# ADSP-2183xW_HPC register map
Vendor: Analog Devices; Series: ADSP-2183xW_HPC; File version: 3.0.3.517
CPU: 
Registers are 32-bit, read-write, reset 0x0 unless marked. A register's access mark holds for its fields unless they carry their own. Offsets are from the block's base; [hi:lo] are bit positions; 'fields as' and 'values as' point back to an identical list.

## MEC1 — Memory Error Controller
Base 0x310A3000
Same registers: MEC2 0x310A4000
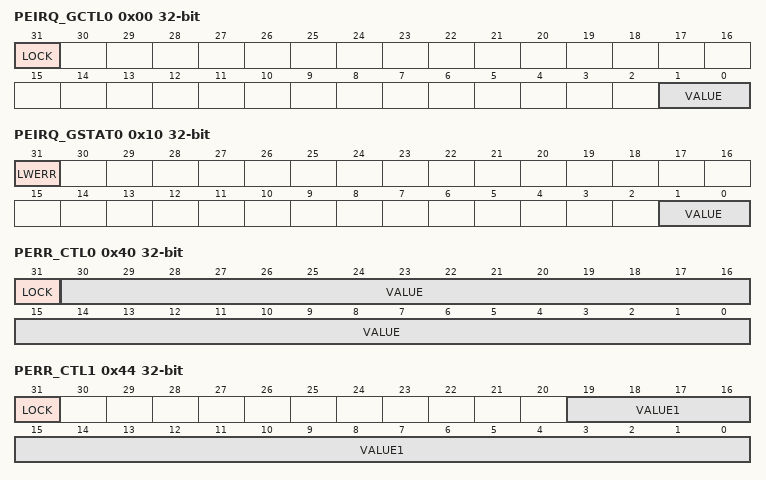
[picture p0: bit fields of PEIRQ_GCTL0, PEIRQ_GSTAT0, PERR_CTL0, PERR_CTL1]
0x00 PEIRQ_GCTL0 — Parity Error Interrupt Request Global Control Register
  [31] LOCK — Parity Error Global Control Register Lock
    0=UNLOCK; 1=LOCK
  [1:0] VALUE range 0x00000000..0x00000003 — VALUE[1:0] Parity Error Global Control
0x10 PEIRQ_GSTAT0 — Parity Error Interrupt Request Global Status Register
  [31] LWERR — Parity Error Global Control Register Lock Write Error
    0=NO_LWERR (No Error); 1=LWERR (Error Occurred)
  [1:0] VALUE ro — VALUE[1:0] Parity Error Global Status
0x40 PERR_CTL0 — Parity Error Control Register
  [31] LOCK
    0=UNLOCK; 1=LOCK
  [30:0] VALUE — Parity Error Control
    32=M33_CODERAM_PE (M33 CodeRAM Parity Error); 64=M33_DATARAM_PE (M33 DataRAM Parity Error)
0x44 PERR_CTL1 — Parity Error Control Register
  [31] LOCK
    0=UNLOCK; 1=LOCK
  [19:0] VALUE1 range 0x00000000..0x000FFFFF — VALUE1[19:0] Parity Error Control
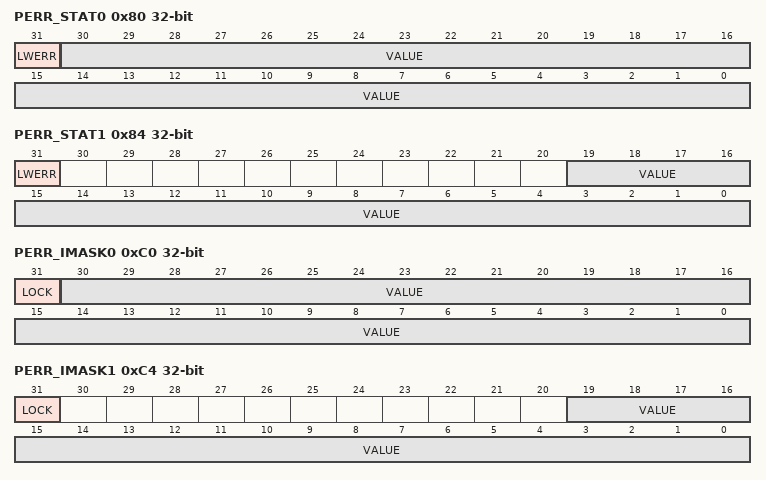
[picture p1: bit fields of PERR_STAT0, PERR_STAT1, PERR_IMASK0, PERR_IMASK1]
0x80 PERR_STAT0 — Parity Error Status Register
  [31] LWERR — Parity Error Control or Interrupt Mask Register Lock Write Error
    0=NO_LWERR (No Error); 1=LWERR (Error Occurred)
  [30:0] VALUE — Parity Error Status
    32=M33_CODERAM_PE_ST (M33 CodeRAM Parity Error); 64=M33_DATARAM_PE_ST (M33 DataRAM Parity Error)
0x84 PERR_STAT1 — Parity Error Status Register
  [31] LWERR — Parity Error Control or Interrupt Mask Register Lock Write Error
    0=NO_LWERR (No Error); 1=LWERR (Error Occurred)
  [19:0] VALUE range 0x00000000..0x000FFFFF — VALUE[19:0] Parity Error Status bit
0xC0 PERR_IMASK0 — Parity Error Interrupt Mask Register
  [31] LOCK — Parity Error Interrupt Mask0 Register Lock
    0=UNLOCK; 1=LOCK
  [30:0] VALUE — Parity Error Interrupt Mask
    values as PERR_CTL0.VALUE
0xC4 PERR_IMASK1 — Parity Error Interrupt Mask Register
  [31] LOCK
    0=UNLOCK; 1=LOCK
  [19:0] VALUE range 0x00000000..0x000FFFFF — VALUE[19:0] Parity Error Interrupt Mask
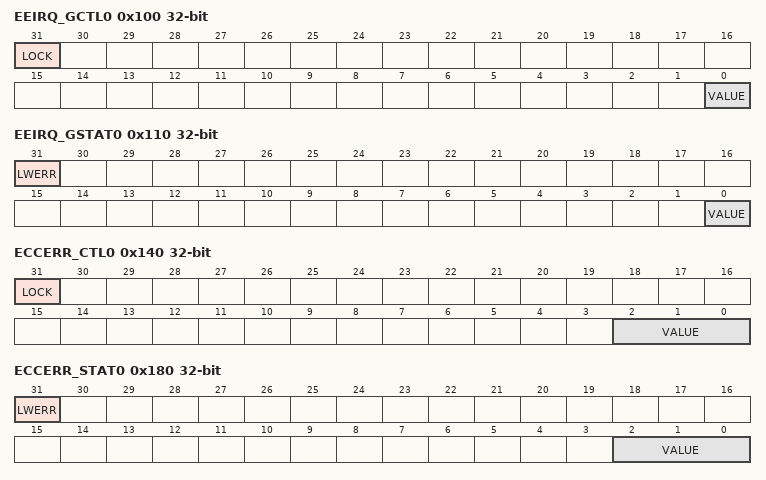
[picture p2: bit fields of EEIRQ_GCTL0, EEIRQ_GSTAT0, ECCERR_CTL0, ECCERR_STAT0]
0x100 EEIRQ_GCTL0 — ECC Error Interrupt Request Global Control Register
  [31] LOCK — ECC Error Global Control Register Lock
    0=UNLOCK; 1=LOCK
  [0] VALUE range 0x00000000..0x00000001 — VALUE[0:0] ECC Error Global Control
0x110 EEIRQ_GSTAT0 — ECC Error Interrupt Request Global Status Register
  [31] LWERR — ECC Error Global Control Register Lock Write Error
    0=NO_LWERR (No Error); 1=LWERR (Error Occurred)
  [0] VALUE ro — VALUE[0:0] ECC Error Global Status
0x140 ECCERR_CTL0 — ECC Error Control Register
  [31] LOCK — ECC Error Control Register Lock
    0=UNLOCK; 1=LOCK
  [2:0] VALUE range 0x00000000..0x00000007 — VALUE[2:0] ECC Error Control
0x180 ECCERR_STAT0 — ECC Error Status Register
  [31] LWERR — ECC Error Control or Interrupt Mask Register Lock Write Error
    0=NO_LWERR (No Error); 1=LWERR (Error Occurred)
  [2:0] VALUE range 0x00000000..0x00000007 — VALUE[2:0] ECC Error Status
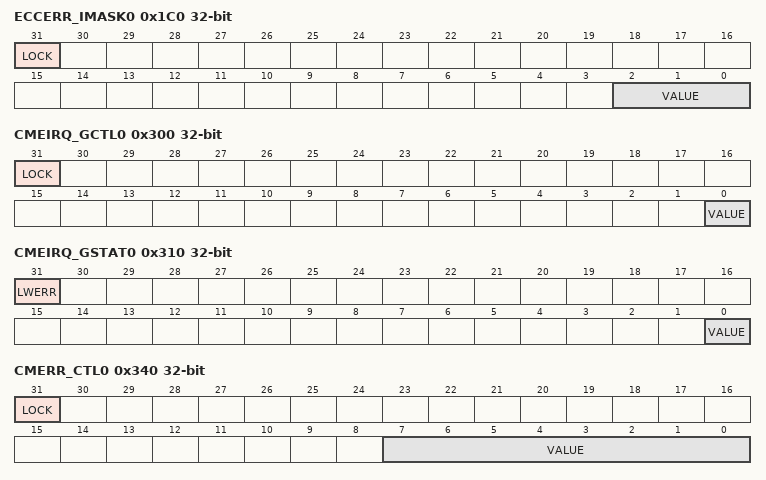
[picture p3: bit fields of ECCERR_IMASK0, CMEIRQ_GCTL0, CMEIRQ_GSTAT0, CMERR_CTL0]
0x1C0 ECCERR_IMASK0 — ECC Error Interrupt Mask Register
  [31] LOCK — ECC Error Interrupt Mask Register Lock
    0=UNLOCK; 1=LOCK
  [2:0] VALUE range 0x00000000..0x00000007 — VALUE[2:0] ECC Error Interrupt Mask
0x300 CMEIRQ_GCTL0 — Core Mem ECC Error Interrupt Request Global Control Register
  [31] LOCK
    0=UNLOCK; 1=LOCK
  [0] VALUE range 0x00000000..0x00000001 — VALUE[0:0] Global Control Value
0x310 CMEIRQ_GSTAT0 — Core Memory ECC Error Interrupt Request Global Status Register
  [31] LWERR — Lock Write Error
    0=NO_LWERR (No Error); 1=LWERR (Error Occurred)
  [0] VALUE range 0x00000000..0x00000001 — VALUE[0:0] Global Control
0x340 CMERR_CTL0 — Core Memory ECC Error Control Register
  [31] LOCK
    0=UNLOCK; 1=LOCK
  [7:0] VALUE range 0x00000000..0x000000FF — VALUE[7:0] Error
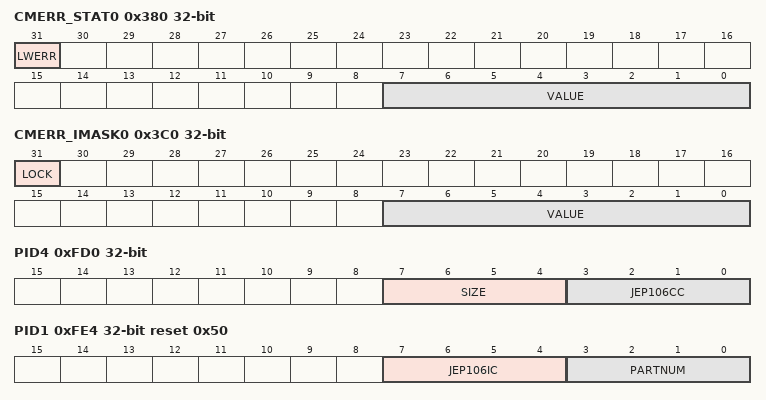
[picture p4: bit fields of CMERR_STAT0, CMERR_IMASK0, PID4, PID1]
0x380 CMERR_STAT0 — Core Memory ECC Error Status Register
  [31] LWERR — Core Memory Error Control or Interrupt Mask Register Lock Write Error
    0=NO_LWERR (No Error); 1=LWERR (Error Occurred)
  [7:0] VALUE range 0x00000000..0x000000FF — VALUE[7:0] Core Memory Error Status
0x3C0 CMERR_IMASK0 — Core Memory ECC Error Interrupt Mask Register
  [31] LOCK — Core Memory Error Interrupt Mask Register Lock
    0=UNLOCK; 1=LOCK
  [7:0] VALUE range 0x00000000..0x000000FF — VALUE[7:0] Core Memory Error
0xF00 CLR — Clear Register
  [0] CLRSTAT range 0x00000000..0x00000001 — Clear Status
0xFD0 PID4 — Peripheral ID4 Register
  [7:4] SIZE ro — Number of 4k Blocks
  [3:0] JEP106CC ro — JEDEC Continuation Code
0xFE0 PID0 reset 0x3 — Peripheral ID0 Register
  [7:0] PARTNUM ro — PARTNUM[7:0] Part Number
0xFE4 PID1 reset 0x50 — Peripheral ID1 Register
  [7:4] JEP106IC ro — JEP106IC[3:0] JEDEC JEP106 Identity
  [3:0] PARTNUM ro — PARTNUM[11:8] Part Number
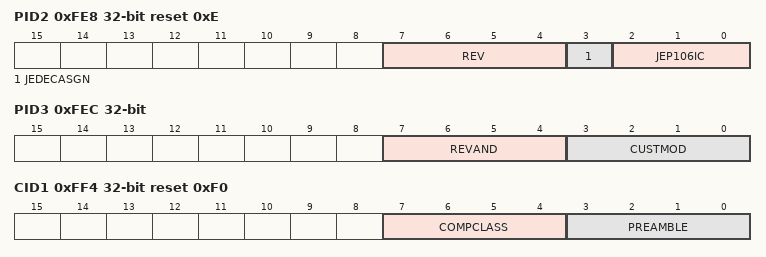
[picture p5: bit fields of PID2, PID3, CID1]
0xFE8 PID2 reset 0xE — Peripheral ID2 Register
  [7:4] REV ro — Peripheral Revision
  [3] JEDECASGN ro — JEDEC Assigned Value
  [2:0] JEP106IC ro — JEP106IC[6:4] JEDEC JEP106 Identity
0xFEC PID3 — Peripheral ID3 Register
  [7:4] REVAND ro — Metal Fix Revision
  [3:0] CUSTMOD ro — Customer Modified
0xFF0 CID0 reset 0xD — Component ID0 Register
  [7:0] PREAMBLE ro — Component ID Preamble
0xFF4 CID1 reset 0xF0 — Component ID1 Register
  [7:4] COMPCLASS ro — Component Class
    9=CS (CoreSight); 15=SYS (System)
  [3:0] PREAMBLE ro — Component ID Preamble
0xFF8 CID2 reset 0x5 — Component ID2 Register
  [7:0] PREAMBLE ro — Component ID Preamble
0xFFC CID3 reset 0xB1 — Component ID3 Register
  [7:0] PREAMBLE ro — Component ID Preamble
